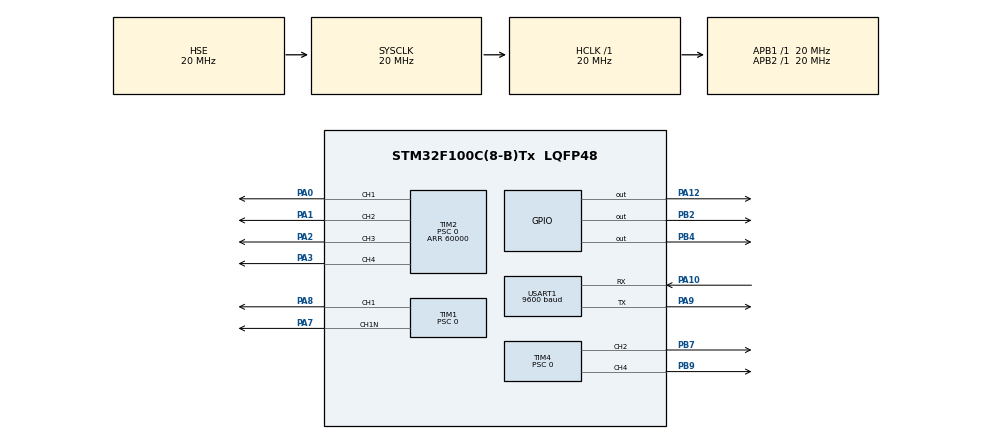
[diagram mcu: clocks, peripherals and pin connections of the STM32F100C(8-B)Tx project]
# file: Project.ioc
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Dma.Request0=USART1_TX
Dma.USART1_TX.0.Direction=DMA_MEMORY_TO_PERIPH
Dma.USART1_TX.0.Instance=DMA1_Channel4
Dma.USART1_TX.0.MemDataAlignment=DMA_MDATAALIGN_BYTE
Dma.USART1_TX.0.MemInc=DMA_MINC_ENABLE
Dma.USART1_TX.0.Mode=DMA_NORMAL
Dma.USART1_TX.0.PeriphDataAlignment=DMA_PDATAALIGN_BYTE
Dma.USART1_TX.0.PeriphInc=DMA_PINC_DISABLE
Dma.USART1_TX.0.Priority=DMA_PRIORITY_LOW
FREERTOS.Tasks01=defaultTask,0,128,StartDefaultTask,Default,NULL
FREERTOS.configTIMER_TASK_STACK_DEPTH=128
FREERTOS.configUSE_TIMERS=1
Mcu.Family=STM32F1
Mcu.Name=STM32F100C(8-B)Tx
Mcu.Package=LQFP48
Mcu.UserConstants=TIMER_PERIOD,201;BUNCH,6059;BUNCH_DUTY,3015;GAP_PERIOD,100;GAP_START,75;GAP_STOP,85
NVIC.DMA1_Channel4_IRQn=true\:5\:0\:false\:false\:true\:true\:false
NVIC.PriorityGroup=NVIC_PRIORITYGROUP_4
NVIC.TIM3_IRQn=true\:5\:0\:false\:false\:true\:true\:true
NVIC.TIM7_IRQn=true\:0\:0\:false\:false\:true\:false\:false
NVIC.TimeBase=TIM7_IRQn
NVIC.TimeBaseIP=TIM7
NVIC.USART1_IRQn=true\:5\:0\:false\:false\:true\:true\:true
PA0-WKUP.GPIO_Speed=GPIO_SPEED_FREQ_HIGH
PA0-WKUP.Signal=S_TIM2_CH1_ETR
PA1.GPIO_ModeDefaultPP=GPIO_MODE_AF_OD
PA1.GPIO_Speed=GPIO_SPEED_FREQ_HIGH
PA1.Signal=S_TIM2_CH2
PA10.Mode=Asynchronous
PA10.Signal=USART1_RX
PA12.Signal=GPIO_Output
PA13.Mode=Serial_Wire
PA13.Signal=SYS_JTMS-SWDIO
PA14.Mode=Serial_Wire
PA14.Signal=SYS_JTCK-SWCLK
PA2.GPIO_Speed=GPIO_SPEED_FREQ_HIGH
PA2.Signal=S_TIM2_CH3
PA3.GPIO_ModeDefaultPP=GPIO_MODE_AF_OD
PA3.GPIO_Speed=GPIO_SPEED_FREQ_HIGH
PA3.Signal=S_TIM2_CH4
PA7.GPIO_Speed=GPIO_SPEED_FREQ_HIGH
PA7.Mode=PWM Generation1 CH1 CH1N
PA7.Signal=TIM1_CH1N
PA8.GPIO_Speed=GPIO_SPEED_FREQ_HIGH
PA8.Signal=S_TIM1_CH1
PA9.Mode=Asynchronous
PA9.Signal=USART1_TX
PB2.Signal=GPIO_Output
PB4.GPIO_ModeDefaultOutputPP=GPIO_MODE_OUTPUT_OD
PB4.Signal=GPIO_Output
PB6.Signal=TIM16_CH1N
PB7.Signal=S_TIM4_CH2
PB8.Signal=S_TIM16_CH1
PB9.GPIO_ModeDefaultPP=GPIO_MODE_AF_OD
PB9.GPIO_Speed=GPIO_SPEED_FREQ_HIGH
PB9.Signal=S_TIM4_CH4
PD0-OSC_IN.Mode=HSE-External-Oscillator
PD0-OSC_IN.Signal=RCC_OSC_IN
PD1-OSC_OUT.Mode=HSE-External-Oscillator
PD1-OSC_OUT.Signal=RCC_OSC_OUT
ProjectManager.HeapSize=0x200
ProjectManager.StackSize=0x400
ProjectManager.TargetToolchain=SW4STM32
RCC.AHBFreq_Value=20000000
RCC.APB1Freq_Value=20000000
RCC.APB1TimFreq_Value=20000000
RCC.APB2Freq_Value=20000000
RCC.APB2TimFreq_Value=20000000
RCC.EnbaleCSS=true
RCC.HCLKFreq_Value=20000000
RCC.HSE_VALUE=20000000
RCC.PLLMUL=RCC_PLL_MUL3
RCC.PLLSource=RCC_PLLSOURCE_HSE
RCC.SYSCLKFreq_VALUE=20000000
RCC.SYSCLKSource=RCC_SYSCLKSOURCE_HSE
SH.S_TIM16_CH1.0=TIM16_CH1
SH.S_TIM1_CH1.0=TIM1_CH1,PWM Generation1 CH1 CH1N
SH.S_TIM2_CH1_ETR.0=TIM2_CH1,PWM Generation1 CH1
SH.S_TIM2_CH2.0=TIM2_CH2,PWM Generation2 CH2
SH.S_TIM2_CH3.0=TIM2_CH3,PWM Generation3 CH3
SH.S_TIM2_CH4.0=TIM2_CH4,PWM Generation4 CH4
SH.S_TIM4_CH2.0=TIM4_CH2,PWM Generation2 CH2
SH.S_TIM4_CH4.0=TIM4_CH4,PWM Generation4 CH4
TIM1.AutoReloadPreload=TIM_AUTORELOAD_PRELOAD_ENABLE
TIM1.Channel-PWM\ Generation1\ CH1\ CH1N=TIM_CHANNEL_1
TIM1.DeadTime=1
TIM1.Period=TIMER_PERIOD
TIM1.Prescaler=0
TIM1.Pulse-PWM\ Generation1\ CH1\ CH1N=TIMER_PERIOD/2
TIM1.TIM_MasterSlaveMode=TIM_MASTERSLAVEMODE_ENABLE
TIM15.Channel-Output\ Compare1\ No\ Output=TIM_CHANNEL_1
TIM15.Channel-Output\ Compare2\ No\ Output=TIM_CHANNEL_2
TIM2.Channel-PWM\ Generation1\ CH1=TIM_CHANNEL_1
TIM2.Channel-PWM\ Generation2\ CH2=TIM_CHANNEL_2
TIM2.Channel-PWM\ Generation3\ CH3=TIM_CHANNEL_3
TIM2.Channel-PWM\ Generation4\ CH4=TIM_CHANNEL_4
TIM2.OCPolarity_1=TIM_OCPOLARITY_LOW
TIM2.OCPolarity_3=TIM_OCPOLARITY_LOW
TIM2.Period=60000
TIM2.Prescaler=0
TIM2.Pulse-PWM\ Generation1\ CH1=5000
TIM2.Pulse-PWM\ Generation2\ CH2=10000
TIM2.Pulse-PWM\ Generation3\ CH3=10000
TIM2.Pulse-PWM\ Generation4\ CH4=15000
TIM3.AutoReloadPreload=TIM_AUTORELOAD_PRELOAD_ENABLE
TIM3.Period=0
TIM3.Prescaler=0
TIM3.TIM_MasterSlaveMode=TIM_MASTERSLAVEMODE_ENABLE
TIM4.Channel-PWM\ Generation2\ CH2=TIM_CHANNEL_2
TIM4.Channel-PWM\ Generation4\ CH4=TIM_CHANNEL_4
TIM4.OCPolarity_2=TIM_OCPOLARITY_LOW
TIM4.Period=BUNCH
TIM4.Prescaler=0
TIM4.Pulse-PWM\ Generation2\ CH2=15000
TIM4.Pulse-PWM\ Generation4\ CH4=20000
TIM4.TIM_MasterSlaveMode=TIM_MASTERSLAVEMODE_ENABLE
USART1.BaudRate=9600
USART1.StopBits=STOPBITS_2
USART1.VirtualMode=VM_ASYNC
VP_FREERTOS_VS_ENABLE.Mode=Enabled
VP_SYS_VS_tim7.Mode=TIM7
VP_TIM15_VS_no_output1.Mode=Output Compare1 No Output
VP_TIM15_VS_no_output2.Mode=Output Compare2 No Output
VP_TIM1_VS_ClockSourceINT.Mode=Internal
VP_TIM1_VS_ClockSourceITR.Mode=TriggerSource_ITR0
VP_TIM3_VS_ClockSourceINT.Mode=Internal
VP_TIM3_VS_ClockSourceITR.Mode=TriggerSource_ITR0
VP_TIM3_VS_ControllerModeTrigger.Mode=Trigger Mode
board=custom

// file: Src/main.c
/* USER CODE BEGIN Header */
/**
  * @brief  Function implementing the defaultTask thread.
  * @param  argument: Not used
  * @retval None
  */
/* USER CODE END Header */

#include "main.h"
#include "cmsis_os.h"

/* USER CODE BEGIN Includes */
#include "common.h"
/* USER CODE END Includes */

TIM_HandleTypeDef htim1;
TIM_HandleTypeDef htim2;
TIM_HandleTypeDef htim3;
TIM_HandleTypeDef htim4;
TIM_HandleTypeDef htim15;

UART_HandleTypeDef huart1;
DMA_HandleTypeDef hdma_usart1_tx;

osThreadId defaultTaskHandle;
/* USER CODE BEGIN PV */
/* Private variables ---------------------------------------------------------*/

/* USER CODE END PV */

void SystemClock_Config(void);
static void MX_GPIO_Init(void);
static void MX_DMA_Init(void);
static void MX_TIM1_Init(void);
static void MX_TIM3_Init(void);
static void MX_USART1_UART_Init(void);
static void MX_TIM2_Init(void);
static void MX_TIM4_Init(void);
static void MX_TIM15_Init(void);
void StartDefaultTask(void const * argument);

/* USER CODE BEGIN PFP */
/* Private function prototypes -----------------------------------------------*/
void StartKernelTask(void const * argument);
/* USER CODE END PFP */

/* USER CODE BEGIN 0 */
volatile UART_t Uart;
volatile State_t State;
/* USER CODE END 0 */

int main(void)
{

  /* MCU Configuration--------------------------------------------------------*/

  /* Reset of all peripherals, Initializes the Flash interface and the Systick. */
  HAL_Init();

  /* Configure the system clock */
  SystemClock_Config();

  /* Initialize all configured peripherals */
  MX_GPIO_Init();
  MX_DMA_Init();
  MX_TIM1_Init();
  MX_TIM3_Init();
  MX_USART1_UART_Init();
  MX_TIM2_Init();
  MX_TIM4_Init();
  MX_TIM15_Init();

  /* Create the thread(s) */
  /* definition and creation of defaultTask */
  osThreadDef(defaultTask, StartDefaultTask, osPriorityNormal, 0, 128);
  defaultTaskHandle = osThreadCreate(osThread(defaultTask), NULL);

  /* USER CODE BEGIN RTOS_THREADS */
  osThreadDef(kernelTask, StartKernelTask, osPriorityNormal, 0, 128);
  osThreadCreate(osThread(kernelTask), NULL);
  /* USER CODE END RTOS_THREADS */

  /* Start scheduler */
  osKernelStart();

  /* We should never get here as control is now taken by the scheduler */

  /* Infinite loop */
  while (1)
  {

  }
}

void SystemClock_Config(void)
{
  RCC_OscInitTypeDef RCC_OscInitStruct = {0};
  RCC_ClkInitTypeDef RCC_ClkInitStruct = {0};

  /**Initializes the CPU, AHB and APB busses clocks
  */
  RCC_OscInitStruct.OscillatorType = RCC_OSCILLATORTYPE_HSE;
  RCC_OscInitStruct.HSEState = RCC_HSE_ON;
  RCC_OscInitStruct.PLL.PLLState = RCC_PLL_NONE;
  if (HAL_RCC_OscConfig(&RCC_OscInitStruct) != HAL_OK)
  {
    Error_Handler();
  }
  /**Initializes the CPU, AHB and APB busses clocks
  */
  RCC_ClkInitStruct.ClockType = RCC_CLOCKTYPE_HCLK|RCC_CLOCKTYPE_SYSCLK
                              |RCC_CLOCKTYPE_PCLK1|RCC_CLOCKTYPE_PCLK2;
  RCC_ClkInitStruct.SYSCLKSource = RCC_SYSCLKSOURCE_HSE;
  RCC_ClkInitStruct.AHBCLKDivider = RCC_SYSCLK_DIV1;
  RCC_ClkInitStruct.APB1CLKDivider = RCC_HCLK_DIV1;
  RCC_ClkInitStruct.APB2CLKDivider = RCC_HCLK_DIV1;

  if (HAL_RCC_ClockConfig(&RCC_ClkInitStruct, FLASH_LATENCY_0) != HAL_OK)
  {
    Error_Handler();
  }
  /**Enables the Clock Security System
  */
  HAL_RCC_EnableCSS();
}

static void MX_TIM1_Init(void)
{

  TIM_ClockConfigTypeDef sClockSourceConfig = {0};
  TIM_SlaveConfigTypeDef sSlaveConfig = {0};
  TIM_MasterConfigTypeDef sMasterConfig = {0};
  TIM_OC_InitTypeDef sConfigOC = {0};
  TIM_BreakDeadTimeConfigTypeDef sBreakDeadTimeConfig = {0};

  htim1.Instance = TIM1;
  htim1.Init.Prescaler = 0;
  htim1.Init.CounterMode = TIM_COUNTERMODE_UP;
  htim1.Init.Period = TIMER_PERIOD;
  htim1.Init.ClockDivision = TIM_CLOCKDIVISION_DIV1;
  htim1.Init.RepetitionCounter = 0;
  htim1.Init.AutoReloadPreload = TIM_AUTORELOAD_PRELOAD_ENABLE;
  if (HAL_TIM_Base_Init(&htim1) != HAL_OK)
  {
    Error_Handler();
  }
  sClockSourceConfig.ClockSource = TIM_CLOCKSOURCE_INTERNAL;
  if (HAL_TIM_ConfigClockSource(&htim1, &sClockSourceConfig) != HAL_OK)
  {
    Error_Handler();
  }
  if (HAL_TIM_PWM_Init(&htim1) != HAL_OK)
  {
    Error_Handler();
  }
  sSlaveConfig.SlaveMode = TIM_SLAVEMODE_DISABLE;
  sSlaveConfig.InputTrigger = TIM_TS_ITR0;
  if (HAL_TIM_SlaveConfigSynchronization(&htim1, &sSlaveConfig) != HAL_OK)
  {
    Error_Handler();
  }
  sMasterConfig.MasterOutputTrigger = TIM_TRGO_RESET;
  sMasterConfig.MasterSlaveMode = TIM_MASTERSLAVEMODE_ENABLE;
  if (HAL_TIMEx_MasterConfigSynchronization(&htim1, &sMasterConfig) != HAL_OK)
  {
    Error_Handler();
  }
  sConfigOC.OCMode = TIM_OCMODE_PWM1;
  sConfigOC.Pulse = TIMER_PERIOD/2;
  sConfigOC.OCPolarity = TIM_OCPOLARITY_HIGH;
  sConfigOC.OCNPolarity = TIM_OCNPOLARITY_HIGH;
  sConfigOC.OCFastMode = TIM_OCFAST_DISABLE;
  sConfigOC.OCIdleState = TIM_OCIDLESTATE_RESET;
  sConfigOC.OCNIdleState = TIM_OCNIDLESTATE_RESET;
  if (HAL_TIM_PWM_ConfigChannel(&htim1, &sConfigOC, TIM_CHANNEL_1) != HAL_OK)
  {
    Error_Handler();
  }
  sBreakDeadTimeConfig.OffStateRunMode = TIM_OSSR_DISABLE;
  sBreakDeadTimeConfig.OffStateIDLEMode = TIM_OSSI_DISABLE;
  sBreakDeadTimeConfig.LockLevel = TIM_LOCKLEVEL_OFF;
  sBreakDeadTimeConfig.DeadTime = 1;
  sBreakDeadTimeConfig.BreakState = TIM_BREAK_DISABLE;
  sBreakDeadTimeConfig.BreakPolarity = TIM_BREAKPOLARITY_HIGH;
  sBreakDeadTimeConfig.AutomaticOutput = TIM_AUTOMATICOUTPUT_DISABLE;
  if (HAL_TIMEx_ConfigBreakDeadTime(&htim1, &sBreakDeadTimeConfig) != HAL_OK)
  {
    Error_Handler();
  }
  HAL_TIM_MspPostInit(&htim1);

}

static void MX_TIM2_Init(void)
{

  TIM_MasterConfigTypeDef sMasterConfig = {0};
  TIM_OC_InitTypeDef sConfigOC = {0};

  htim2.Instance = TIM2;
  htim2.Init.Prescaler = 0;
  htim2.Init.CounterMode = TIM_COUNTERMODE_UP;
  htim2.Init.Period = 60000;
  htim2.Init.ClockDivision = TIM_CLOCKDIVISION_DIV1;
  htim2.Init.AutoReloadPreload = TIM_AUTORELOAD_PRELOAD_DISABLE;
  if (HAL_TIM_PWM_Init(&htim2) != HAL_OK)
  {
    Error_Handler();
  }
  sMasterConfig.MasterOutputTrigger = TIM_TRGO_RESET;
  sMasterConfig.MasterSlaveMode = TIM_MASTERSLAVEMODE_DISABLE;
  if (HAL_TIMEx_MasterConfigSynchronization(&htim2, &sMasterConfig) != HAL_OK)
  {
    Error_Handler();
  }
  sConfigOC.OCMode = TIM_OCMODE_PWM1;
  sConfigOC.Pulse = 5000;
  sConfigOC.OCPolarity = TIM_OCPOLARITY_LOW;
  sConfigOC.OCFastMode = TIM_OCFAST_DISABLE;
  if (HAL_TIM_PWM_ConfigChannel(&htim2, &sConfigOC, TIM_CHANNEL_1) != HAL_OK)
  {
    Error_Handler();
  }
  sConfigOC.Pulse = 10000;
  sConfigOC.OCPolarity = TIM_OCPOLARITY_HIGH;
  if (HAL_TIM_PWM_ConfigChannel(&htim2, &sConfigOC, TIM_CHANNEL_2) != HAL_OK)
  {
    Error_Handler();
  }
  sConfigOC.OCPolarity = TIM_OCPOLARITY_LOW;
  if (HAL_TIM_PWM_ConfigChannel(&htim2, &sConfigOC, TIM_CHANNEL_3) != HAL_OK)
  {
    Error_Handler();
  }
  sConfigOC.Pulse = 15000;
  sConfigOC.OCPolarity = TIM_OCPOLARITY_HIGH;
  if (HAL_TIM_PWM_ConfigChannel(&htim2, &sConfigOC, TIM_CHANNEL_4) != HAL_OK)
  {
    Error_Handler();
  }
  HAL_TIM_MspPostInit(&htim2);

}

static void MX_TIM3_Init(void)
{

  TIM_ClockConfigTypeDef sClockSourceConfig = {0};
  TIM_SlaveConfigTypeDef sSlaveConfig = {0};
  TIM_MasterConfigTypeDef sMasterConfig = {0};

  htim3.Instance = TIM3;
  htim3.Init.Prescaler = 0;
  htim3.Init.CounterMode = TIM_COUNTERMODE_UP;
  htim3.Init.Period = GAP_PERIOD;
  htim3.Init.ClockDivision = TIM_CLOCKDIVISION_DIV1;
  htim3.Init.AutoReloadPreload = TIM_AUTORELOAD_PRELOAD_ENABLE;
  if (HAL_TIM_Base_Init(&htim3) != HAL_OK)
  {
    Error_Handler();
  }
  sClockSourceConfig.ClockSource = TIM_CLOCKSOURCE_INTERNAL;
  if (HAL_TIM_ConfigClockSource(&htim3, &sClockSourceConfig) != HAL_OK)
  {
    Error_Handler();
  }
  sSlaveConfig.SlaveMode = TIM_SLAVEMODE_TRIGGER;
  sSlaveConfig.InputTrigger = TIM_TS_ITR0;
  if (HAL_TIM_SlaveConfigSynchronization(&htim3, &sSlaveConfig) != HAL_OK)
  {
    Error_Handler();
  }
  sMasterConfig.MasterOutputTrigger = TIM_TRGO_RESET;
  sMasterConfig.MasterSlaveMode = TIM_MASTERSLAVEMODE_ENABLE;
  if (HAL_TIMEx_MasterConfigSynchronization(&htim3, &sMasterConfig) != HAL_OK)
  {
    Error_Handler();
  }

}

static void MX_TIM4_Init(void)
{

  TIM_MasterConfigTypeDef sMasterConfig = {0};
  TIM_OC_InitTypeDef sConfigOC = {0};

  htim4.Instance = TIM4;
  htim4.Init.Prescaler = 0;
  htim4.Init.CounterMode = TIM_COUNTERMODE_UP;
  htim4.Init.Period = BUNCH;
  htim4.Init.ClockDivision = TIM_CLOCKDIVISION_DIV1;
  htim4.Init.AutoReloadPreload = TIM_AUTORELOAD_PRELOAD_DISABLE;
  if (HAL_TIM_PWM_Init(&htim4) != HAL_OK)
  {
    Error_Handler();
  }
  sMasterConfig.MasterOutputTrigger = TIM_TRGO_RESET;
  sMasterConfig.MasterSlaveMode = TIM_MASTERSLAVEMODE_ENABLE;
  if (HAL_TIMEx_MasterConfigSynchronization(&htim4, &sMasterConfig) != HAL_OK)
  {
    Error_Handler();
  }
  sConfigOC.OCMode = TIM_OCMODE_PWM1;
  sConfigOC.Pulse = 15000;
  sConfigOC.OCPolarity = TIM_OCPOLARITY_LOW;
  sConfigOC.OCFastMode = TIM_OCFAST_DISABLE;
  if (HAL_TIM_PWM_ConfigChannel(&htim4, &sConfigOC, TIM_CHANNEL_2) != HAL_OK)
  {
    Error_Handler();
  }
  sConfigOC.Pulse = 20000;
  sConfigOC.OCPolarity = TIM_OCPOLARITY_HIGH;
  if (HAL_TIM_PWM_ConfigChannel(&htim4, &sConfigOC, TIM_CHANNEL_4) != HAL_OK)
  {
    Error_Handler();
  }
  HAL_TIM_MspPostInit(&htim4);

}

static void MX_TIM15_Init(void)
{

  TIM_MasterConfigTypeDef sMasterConfig = {0};
  TIM_OC_InitTypeDef sConfigOC = {0};
  TIM_BreakDeadTimeConfigTypeDef sBreakDeadTimeConfig = {0};

  htim15.Instance = TIM15;
  htim15.Init.Prescaler = 0;
  htim15.Init.CounterMode = TIM_COUNTERMODE_UP;
  htim15.Init.Period = 0;
  htim15.Init.ClockDivision = TIM_CLOCKDIVISION_DIV1;
  htim15.Init.RepetitionCounter = 0;
  htim15.Init.AutoReloadPreload = TIM_AUTORELOAD_PRELOAD_DISABLE;
  if (HAL_TIM_OC_Init(&htim15) != HAL_OK)
  {
    Error_Handler();
  }
  sMasterConfig.MasterOutputTrigger = TIM_TRGO_RESET;
  sMasterConfig.MasterSlaveMode = TIM_MASTERSLAVEMODE_DISABLE;
  if (HAL_TIMEx_MasterConfigSynchronization(&htim15, &sMasterConfig) != HAL_OK)
  {
    Error_Handler();
  }
  sConfigOC.OCMode = TIM_OCMODE_TIMING;
  sConfigOC.Pulse = 0;
  sConfigOC.OCPolarity = TIM_OCPOLARITY_HIGH;
  sConfigOC.OCNPolarity = TIM_OCNPOLARITY_HIGH;
  sConfigOC.OCFastMode = TIM_OCFAST_DISABLE;
  sConfigOC.OCIdleState = TIM_OCIDLESTATE_RESET;
  sConfigOC.OCNIdleState = TIM_OCNIDLESTATE_RESET;
  if (HAL_TIM_OC_ConfigChannel(&htim15, &sConfigOC, TIM_CHANNEL_1) != HAL_OK)
  {
    Error_Handler();
  }
  if (HAL_TIM_OC_ConfigChannel(&htim15, &sConfigOC, TIM_CHANNEL_2) != HAL_OK)
  {
    Error_Handler();
  }
  sBreakDeadTimeConfig.OffStateRunMode = TIM_OSSR_DISABLE;
  sBreakDeadTimeConfig.OffStateIDLEMode = TIM_OSSI_DISABLE;
  sBreakDeadTimeConfig.LockLevel = TIM_LOCKLEVEL_OFF;
  sBreakDeadTimeConfig.DeadTime = 0;
  sBreakDeadTimeConfig.BreakState = TIM_BREAK_DISABLE;
  sBreakDeadTimeConfig.BreakPolarity = TIM_BREAKPOLARITY_HIGH;
  sBreakDeadTimeConfig.AutomaticOutput = TIM_AUTOMATICOUTPUT_DISABLE;
  if (HAL_TIMEx_ConfigBreakDeadTime(&htim15, &sBreakDeadTimeConfig) != HAL_OK)
  {
    Error_Handler();
  }

}

static void MX_USART1_UART_Init(void)
{

  huart1.Instance = USART1;
  huart1.Init.BaudRate = 9600;
  huart1.Init.WordLength = UART_WORDLENGTH_8B;
  huart1.Init.StopBits = UART_STOPBITS_2;
  huart1.Init.Parity = UART_PARITY_NONE;
  huart1.Init.Mode = UART_MODE_TX_RX;
  huart1.Init.HwFlowCtl = UART_HWCONTROL_NONE;
  huart1.Init.OverSampling = UART_OVERSAMPLING_16;
  if (HAL_UART_Init(&huart1) != HAL_OK)
  {
    Error_Handler();
  }

}

static void MX_DMA_Init(void)
{
  /* DMA controller clock enable */
  __HAL_RCC_DMA1_CLK_ENABLE();

  /* DMA interrupt init */
  /* DMA1_Channel4_IRQn interrupt configuration */
  HAL_NVIC_SetPriority(DMA1_Channel4_IRQn, 5, 0);
  HAL_NVIC_EnableIRQ(DMA1_Channel4_IRQn);

}

static void MX_GPIO_Init(void)
{
  GPIO_InitTypeDef GPIO_InitStruct = {0};

  /* GPIO Ports Clock Enable */
  __HAL_RCC_GPIOD_CLK_ENABLE();
  __HAL_RCC_GPIOA_CLK_ENABLE();
  __HAL_RCC_GPIOB_CLK_ENABLE();

  /*Configure GPIO pin Output Level */
  HAL_GPIO_WritePin(GPIOB, GPIO_PIN_2|GPIO_PIN_4, GPIO_PIN_RESET);

  /*Configure GPIO pin Output Level */
  HAL_GPIO_WritePin(GPIOA, GPIO_PIN_12, GPIO_PIN_RESET);

  /*Configure GPIO pin : PB2 */
  GPIO_InitStruct.Pin = GPIO_PIN_2;
  GPIO_InitStruct.Mode = GPIO_MODE_OUTPUT_PP;
  GPIO_InitStruct.Pull = GPIO_NOPULL;
  GPIO_InitStruct.Speed = GPIO_SPEED_FREQ_LOW;
  HAL_GPIO_Init(GPIOB, &GPIO_InitStruct);

  /*Configure GPIO pin : PA12 */
  GPIO_InitStruct.Pin = GPIO_PIN_12;
  GPIO_InitStruct.Mode = GPIO_MODE_OUTPUT_PP;
  GPIO_InitStruct.Pull = GPIO_NOPULL;
  GPIO_InitStruct.Speed = GPIO_SPEED_FREQ_LOW;
  HAL_GPIO_Init(GPIOA, &GPIO_InitStruct);

  /*Configure GPIO pin : PB4 */
  GPIO_InitStruct.Pin = GPIO_PIN_4;
  GPIO_InitStruct.Mode = GPIO_MODE_OUTPUT_OD;
  GPIO_InitStruct.Pull = GPIO_NOPULL;
  GPIO_InitStruct.Speed = GPIO_SPEED_FREQ_LOW;
  HAL_GPIO_Init(GPIOB, &GPIO_InitStruct);

  /*Configure GPIO pins : PB6 PB8 */
  GPIO_InitStruct.Pin = GPIO_PIN_6|GPIO_PIN_8;
  GPIO_InitStruct.Mode = GPIO_MODE_AF_PP;
  GPIO_InitStruct.Speed = GPIO_SPEED_FREQ_LOW;
  HAL_GPIO_Init(GPIOB, &GPIO_InitStruct);

}

/* USER CODE BEGIN 4 */
void StartKernelTask(void const * argument)
{
	KERNEL_Init();
	KERNEL_Task();
}
/* USER CODE END 4 */

void StartDefaultTask(void const * argument)
{

  /* USER CODE BEGIN 5 */
  /* Infinite loop */
	PM_Init();
	PM_Task();
  /*for(;;)
  {
	  HAL_GPIO_TogglePin(GPIOA, GPIO_PIN_12);
	  osDelay(500);
  }*/

  /* USER CODE END 5 */
}

void HAL_TIM_PeriodElapsedCallback(TIM_HandleTypeDef *htim)
{
  if (htim->Instance == TIM7) {
    HAL_IncTick();
  }
  /* USER CODE BEGIN Callback 1 */
  else{
	  KERNEL_TIM_PeriodElapsedCallback(htim);
  }
  /* USER CODE END Callback 1 */
}

void Error_Handler(void)
{
  while(1)
  {
  }
}

/************************ (C) COPYRIGHT STMicroelectronics *****END OF FILE****/
